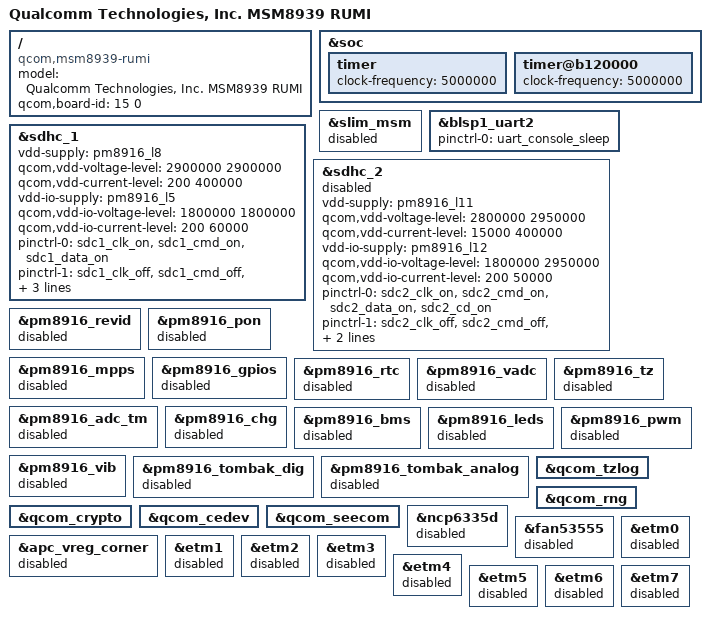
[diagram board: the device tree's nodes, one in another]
/* Copyright (c) 2014, The Linux Foundation. All rights reserved.
 *
 * This program is free software; you can redistribute it and/or modify
 * it under the terms of the GNU General Public License version 2 and
 * only version 2 as published by the Free Software Foundation.
 *
 * This program is distributed in the hope that it will be useful,
 * but WITHOUT ANY WARRANTY; without even the implied warranty of
 * MERCHANTABILITY or FITNESS FOR A PARTICULAR PURPOSE.  See the
 * GNU General Public License for more details.
 */

/dts-v1/;

#include "msm8939.dtsi"
#include "msm8939-pinctrl.dtsi"

/ {
	model = "Qualcomm Technologies, Inc. MSM8939 RUMI";
	compatible = "qcom,msm8939-rumi", "qcom,msm8939", "qcom,rumi";
	qcom,board-id= <15 0>;
};

&soc {
	timer {
		clock-frequency = <5000000>;
	};

	timer@b120000 {
		clock-frequency = <5000000>;
	};
};

&slim_msm {
	status = "disabled";
};

&blsp1_uart2 {
	status = "ok";
	pinctrl-names = "default";
	pinctrl-0 = <&uart_console_sleep>;
};

&sdhc_1 {
	vdd-supply = <&pm8916_l8>;
	qcom,vdd-voltage-level = <2900000 2900000>;
	qcom,vdd-current-level = <200 400000>;

	vdd-io-supply = <&pm8916_l5>;
	qcom,vdd-io-voltage-level = <1800000 1800000>;
	qcom,vdd-io-current-level = <200 60000>;

	pinctrl-names = "active", "sleep";
	pinctrl-0 = <&sdc1_clk_on &sdc1_cmd_on &sdc1_data_on>;
	pinctrl-1 = <&sdc1_clk_off &sdc1_cmd_off &sdc1_data_off>;

	qcom,clk-rates = <400000 19200000>;
	qcom,nonremovable;
	/delete-property/ qcom,bus-speed-mode;
	status = "ok";
};

&sdhc_2 {
	vdd-supply = <&pm8916_l11>;
	qcom,vdd-voltage-level = <2800000 2950000>;
	qcom,vdd-current-level = <15000 400000>;

	vdd-io-supply = <&pm8916_l12>;
	qcom,vdd-io-voltage-level = <1800000 2950000>;
	qcom,vdd-io-current-level = <200 50000>;

	pinctrl-names = "active", "sleep";
	pinctrl-0 = <&sdc2_clk_on &sdc2_cmd_on &sdc2_data_on &sdc2_cd_on>;
	pinctrl-1 = <&sdc2_clk_off &sdc2_cmd_off &sdc2_data_off &sdc2_cd_off>;

	qcom,clk-rates = <400000 19200000>;

	status = "disabled";
};

&pm8916_revid {
	status = "disabled";
};

&pm8916_pon {
	status = "disabled";
};

&pm8916_mpps {
	status = "disabled";
};

&pm8916_gpios {
	status = "disabled";
};

&pm8916_rtc {
	status = "disabled";
};

&pm8916_vadc {
	status = "disabled";
};

&pm8916_tz {
	status = "disabled";
};

&pm8916_adc_tm {
	status = "disabled";
};

&pm8916_chg {
	status = "disabled";
};

&pm8916_bms {
	status = "disabled";
};

&pm8916_leds {
	status = "disabled";
};

&pm8916_pwm {
	status = "disabled";
};

&pm8916_vib {
	status = "disabled";
};

&pm8916_tombak_dig {
	status = "disabled";
};

&pm8916_tombak_analog {
	status = "disabled";
};

&qcom_tzlog {
	status = "okay";
};

&qcom_rng {
	status = "okay";
};

&qcom_crypto {
	status = "okay";
};

&qcom_cedev {
	status = "okay";
};

&qcom_seecom {
	status = "okay";
};

&ncp6335d {
	status = "disabled";
};

&fan53555 {
	status = "disabled";
};

&apc_vreg_corner {
	status = "disabled";
};

&etm0 {
	status = "disabled";
};

&etm1 {
	status = "disabled";
};

&etm2 {
	status = "disabled";
};

&etm3 {
	status = "disabled";
};

&etm4 {
	status = "disabled";
};

&etm5 {
	status = "disabled";
};

&etm6 {
	status = "disabled";
};

&etm7 {
	status = "disabled";
};
